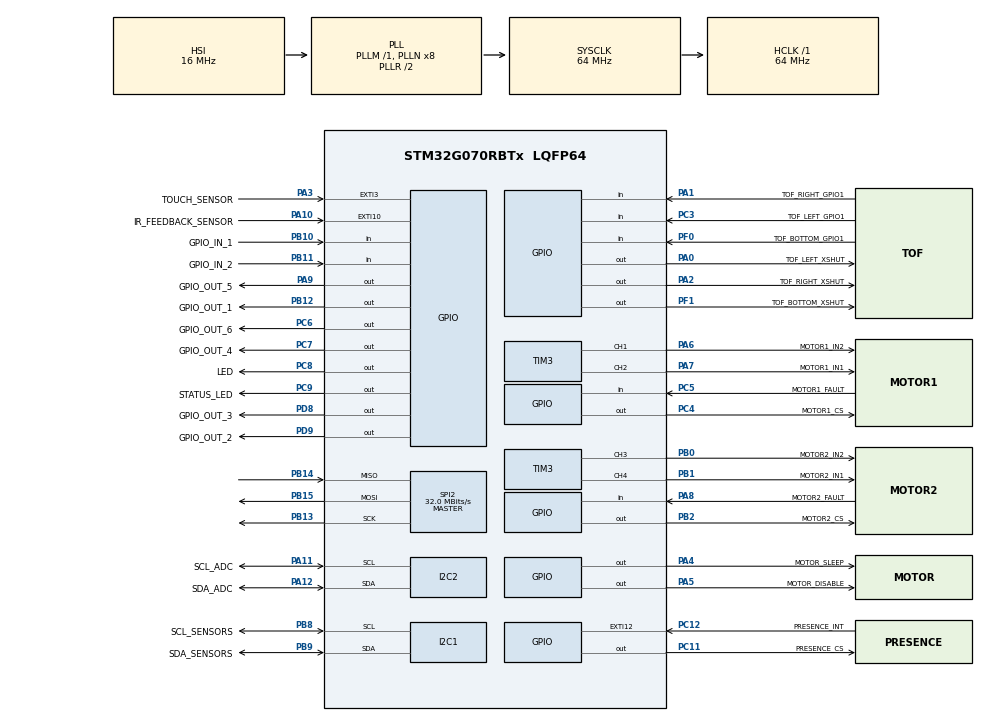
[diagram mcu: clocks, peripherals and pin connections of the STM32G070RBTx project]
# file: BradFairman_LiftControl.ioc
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I2C1.Timing=0x10707DBC
Mcu.Family=STM32G0
Mcu.Name=STM32G070RBTx
Mcu.Package=LQFP64
NVIC.EXTI2_3_IRQn=true\:0\:0\:false\:false\:true\:true\:true\:true
NVIC.EXTI4_15_IRQn=true\:0\:0\:false\:false\:true\:true\:true\:true
NVIC.TIM3_IRQn=true\:0\:0\:false\:false\:true\:true\:true\:true
PA0.GPIO_Label=TOF_LEFT_XSHUT
PA0.Signal=GPIO_Output
PA1.GPIO_Label=TOF_RIGHT_GPIO1
PA1.Signal=GPIO_Input
PA10.GPIO_Label=IR_FEEDBACK_SENSOR
PA10.GPIO_ModeDefaultEXTI=GPIO_MODE_IT_RISING_FALLING
PA10.Signal=GPXTI10
PA11\ [PA9].GPIO_Label=SCL_ADC
PA11\ [PA9].Mode=I2C
PA11\ [PA9].Signal=I2C2_SCL
PA12\ [PA10].GPIO_Label=SDA_ADC
PA12\ [PA10].Mode=I2C
PA12\ [PA10].Signal=I2C2_SDA
PA13.Mode=Serial_Wire
PA13.Signal=SYS_SWDIO
PA14-BOOT0.Mode=Serial_Wire
PA14-BOOT0.Signal=SYS_SWCLK
PA2.GPIO_Label=TOF_RIGHT_XSHUT
PA2.Signal=GPIO_Output
PA3.GPIO_Label=TOUCH_SENSOR
PA3.GPIO_ModeDefaultEXTI=GPIO_MODE_IT_RISING_FALLING
PA3.Signal=GPXTI3
PA4.GPIO_Label=MOTOR_SLEEP
PA4.Signal=GPIO_Output
PA5.GPIO_Label=MOTOR_DISABLE
PA5.Signal=GPIO_Output
PA6.GPIO_Label=MOTOR1_IN2
PA6.GPIO_PuPd=GPIO_PULLDOWN
PA6.GPIO_Speed=GPIO_SPEED_FREQ_HIGH
PA6.Signal=S_TIM3_CH1
PA7.GPIO_Label=MOTOR1_IN1
PA7.GPIO_PuPd=GPIO_PULLDOWN
PA7.GPIO_Speed=GPIO_SPEED_FREQ_HIGH
PA7.Signal=S_TIM3_CH2
PA8.GPIO_Label=MOTOR2_FAULT
PA8.Signal=GPIO_Input
PA9.GPIO_Label=GPIO_OUT_5
PA9.Signal=GPIO_Output
PB0.GPIO_Label=MOTOR2_IN2
PB0.GPIO_PuPd=GPIO_PULLDOWN
PB0.GPIO_Speed=GPIO_SPEED_FREQ_HIGH
PB0.Signal=S_TIM3_CH3
PB1.GPIO_Label=MOTOR2_IN1
PB1.GPIO_PuPd=GPIO_PULLDOWN
PB1.GPIO_Speed=GPIO_SPEED_FREQ_HIGH
PB1.Signal=S_TIM3_CH4
PB10.GPIO_Label=GPIO_IN_1
PB10.Signal=GPIO_Input
PB11.GPIO_Label=GPIO_IN_2
PB11.Signal=GPIO_Input
PB12.GPIO_Label=GPIO_OUT_1
PB12.Signal=GPIO_Output
PB13.Mode=Full_Duplex_Master
PB13.Signal=SPI2_SCK
PB14.Mode=Full_Duplex_Master
PB14.Signal=SPI2_MISO
PB15.Mode=Full_Duplex_Master
PB15.Signal=SPI2_MOSI
PB2.GPIO_Label=MOTOR2_CS
PB2.PinState=GPIO_PIN_SET
PB2.Signal=GPIO_Output
PB8.GPIO_Label=SCL_SENSORS
PB8.Mode=I2C
PB8.Signal=I2C1_SCL
PB9.GPIO_Label=SDA_SENSORS
PB9.Mode=I2C
PB9.Signal=I2C1_SDA
PC11.GPIO_Label=PRESENCE_CS
PC11.Signal=GPIO_Output
PC12.GPIO_Label=PRESENCE_INT
PC12.Signal=GPXTI12
PC3.GPIO_Label=TOF_LEFT_GPIO1
PC3.Signal=GPIO_Input
PC4.GPIO_Label=MOTOR1_CS
PC4.PinState=GPIO_PIN_SET
PC4.Signal=GPIO_Output
PC5.GPIO_Label=MOTOR1_FAULT
PC5.Signal=GPIO_Input
PC6.GPIO_Label=GPIO_OUT_6
PC6.Signal=GPIO_Output
PC7.GPIO_Label=GPIO_OUT_4
PC7.Signal=GPIO_Output
PC8.GPIO_Label=LED
PC8.Signal=GPIO_Output
PC9.GPIO_Label=STATUS_LED
PC9.Signal=GPIO_Output
PD8.GPIO_Label=GPIO_OUT_3
PD8.Signal=GPIO_Output
PD9.GPIO_Label=GPIO_OUT_2
PD9.Signal=GPIO_Output
PF0-OSC_IN\ (PF0).GPIO_Label=TOF_BOTTOM_GPIO1
PF0-OSC_IN\ (PF0).Signal=GPIO_Input
PF1-OSC_OUT\ (PF1).GPIO_Label=TOF_BOTTOM_XSHUT
PF1-OSC_OUT\ (PF1).Signal=GPIO_Output
ProjectManager.HeapSize=0x200
ProjectManager.StackSize=0x400
ProjectManager.TargetToolchain=STM32CubeIDE
RCC.ADCFreq_Value=64000000
RCC.AHBFreq_Value=64000000
RCC.CortexFreq_Value=64000000
RCC.EXTERNAL_CLOCK_VALUE=48000
RCC.HCLKFreq_Value=64000000
RCC.HSE_VALUE=8000000
RCC.HSI_VALUE=16000000
RCC.LSE_VALUE=32768
RCC.SYSCLKFreq_VALUE=64000000
RCC.SYSCLKSource=RCC_SYSCLKSOURCE_PLLCLK
RCC.VCOOutputFreq_Value=128000000
SH.S_TIM3_CH1.0=TIM3_CH1,PWM Generation1 CH1
SH.S_TIM3_CH2.0=TIM3_CH2,PWM Generation2 CH2
SH.S_TIM3_CH3.0=TIM3_CH3,PWM Generation3 CH3
SH.S_TIM3_CH4.0=TIM3_CH4,PWM Generation4 CH4
SPI2.CalculateBaudRate=32.0 MBits/s
SPI2.DataSize=SPI_DATASIZE_8BIT
SPI2.Direction=SPI_DIRECTION_2LINES
SPI2.Mode=SPI_MODE_MASTER
SPI2.VirtualType=VM_MASTER
TIM3.Channel-PWM\ Generation1\ CH1=TIM_CHANNEL_1
TIM3.Channel-PWM\ Generation2\ CH2=TIM_CHANNEL_2
TIM3.Channel-PWM\ Generation3\ CH3=TIM_CHANNEL_3
TIM3.Channel-PWM\ Generation4\ CH4=TIM_CHANNEL_4
VP_SYS_VS_DBSignals.Mode=DisableDeadBatterySignals
VP_TIM3_VS_ClockSourceINT.Mode=Internal
board=custom

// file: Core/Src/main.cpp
/* USER CODE BEGIN Header */
/**
  ******************************************************************************
  * @file           : main.c
  * @brief          : Main program body
  ******************************************************************************
  * @attention
  *
  * Copyright (c) 2024 STMicroelectronics.
  * All rights reserved.
  *
  * This software is licensed under terms that can be found in the LICENSE file
  * in the root directory of this software component.
  * If no LICENSE file comes with this software, it is provided AS-IS.
  *
  ******************************************************************************
  */
/* USER CODE END Header */
#include "main.h"

/* USER CODE BEGIN Includes */
#include <mainApp.hpp>
/* USER CODE END Includes */

I2C_HandleTypeDef hi2c1;
I2C_HandleTypeDef hi2c2;

SPI_HandleTypeDef hspi2;

TIM_HandleTypeDef htim3;

/* USER CODE BEGIN PV */
mainApp liftControl(&hspi2, &hi2c1, &hi2c2, &htim3);

/* USER CODE END PV */

void SystemClock_Config(void);
static void MX_GPIO_Init(void);
static void MX_I2C1_Init(void);
static void MX_I2C2_Init(void);
static void MX_SPI2_Init(void);
static void MX_TIM3_Init(void);
/* USER CODE BEGIN PFP */

//bool led_status = false;

/* USER CODE END PFP */

int main(void)
{

  /* MCU Configuration--------------------------------------------------------*/

  /* Reset of all peripherals, Initializes the Flash interface and the Systick. */
  HAL_Init();

  /* Configure the system clock */
  SystemClock_Config();

  /* Initialize all configured peripherals */
  MX_GPIO_Init();
  MX_I2C1_Init();
  MX_I2C2_Init();
  MX_SPI2_Init();
  MX_TIM3_Init();
  /* USER CODE BEGIN 2 */
  liftControl.initialize();

  liftControl.loop();

  /* USER CODE END 2 */

  /* Infinite loop */
  while (1)
  {

  }
}

void SystemClock_Config(void)
{
  RCC_OscInitTypeDef RCC_OscInitStruct = {0};
  RCC_ClkInitTypeDef RCC_ClkInitStruct = {0};

  /** Configure the main internal regulator output voltage
  */
  HAL_PWREx_ControlVoltageScaling(PWR_REGULATOR_VOLTAGE_SCALE1);

  /** Initializes the RCC Oscillators according to the specified parameters
  * in the RCC_OscInitTypeDef structure.
  */
  RCC_OscInitStruct.OscillatorType = RCC_OSCILLATORTYPE_HSI;
  RCC_OscInitStruct.HSIState = RCC_HSI_ON;
  RCC_OscInitStruct.HSIDiv = RCC_HSI_DIV1;
  RCC_OscInitStruct.HSICalibrationValue = RCC_HSICALIBRATION_DEFAULT;
  RCC_OscInitStruct.PLL.PLLState = RCC_PLL_ON;
  RCC_OscInitStruct.PLL.PLLSource = RCC_PLLSOURCE_HSI;
  RCC_OscInitStruct.PLL.PLLM = RCC_PLLM_DIV1;
  RCC_OscInitStruct.PLL.PLLN = 8;
  RCC_OscInitStruct.PLL.PLLP = RCC_PLLP_DIV2;
  RCC_OscInitStruct.PLL.PLLR = RCC_PLLR_DIV2;
  if (HAL_RCC_OscConfig(&RCC_OscInitStruct) != HAL_OK)
  {
    Error_Handler();
  }

  /** Initializes the CPU, AHB and APB buses clocks
  */
  RCC_ClkInitStruct.ClockType = RCC_CLOCKTYPE_HCLK|RCC_CLOCKTYPE_SYSCLK
                              |RCC_CLOCKTYPE_PCLK1;
  RCC_ClkInitStruct.SYSCLKSource = RCC_SYSCLKSOURCE_PLLCLK;
  RCC_ClkInitStruct.AHBCLKDivider = RCC_SYSCLK_DIV1;
  RCC_ClkInitStruct.APB1CLKDivider = RCC_HCLK_DIV1;

  if (HAL_RCC_ClockConfig(&RCC_ClkInitStruct, FLASH_LATENCY_2) != HAL_OK)
  {
    Error_Handler();
  }
}

static void MX_I2C1_Init(void)
{

  hi2c1.Instance = I2C1;
  hi2c1.Init.Timing = 0x10707DBC;
  hi2c1.Init.OwnAddress1 = 0;
  hi2c1.Init.AddressingMode = I2C_ADDRESSINGMODE_7BIT;
  hi2c1.Init.DualAddressMode = I2C_DUALADDRESS_DISABLE;
  hi2c1.Init.OwnAddress2 = 0;
  hi2c1.Init.OwnAddress2Masks = I2C_OA2_NOMASK;
  hi2c1.Init.GeneralCallMode = I2C_GENERALCALL_DISABLE;
  hi2c1.Init.NoStretchMode = I2C_NOSTRETCH_DISABLE;
  if (HAL_I2C_Init(&hi2c1) != HAL_OK)
  {
    Error_Handler();
  }

  /** Configure Analogue filter
  */
  if (HAL_I2CEx_ConfigAnalogFilter(&hi2c1, I2C_ANALOGFILTER_ENABLE) != HAL_OK)
  {
    Error_Handler();
  }

  /** Configure Digital filter
  */
  if (HAL_I2CEx_ConfigDigitalFilter(&hi2c1, 0) != HAL_OK)
  {
    Error_Handler();
  }

}

static void MX_I2C2_Init(void)
{

  hi2c2.Instance = I2C2;
  hi2c2.Init.Timing = 0x00303D5B;
  hi2c2.Init.OwnAddress1 = 0;
  hi2c2.Init.AddressingMode = I2C_ADDRESSINGMODE_7BIT;
  hi2c2.Init.DualAddressMode = I2C_DUALADDRESS_DISABLE;
  hi2c2.Init.OwnAddress2 = 0;
  hi2c2.Init.OwnAddress2Masks = I2C_OA2_NOMASK;
  hi2c2.Init.GeneralCallMode = I2C_GENERALCALL_DISABLE;
  hi2c2.Init.NoStretchMode = I2C_NOSTRETCH_DISABLE;
  if (HAL_I2C_Init(&hi2c2) != HAL_OK)
  {
    Error_Handler();
  }

  /** Configure Analogue filter
  */
  if (HAL_I2CEx_ConfigAnalogFilter(&hi2c2, I2C_ANALOGFILTER_ENABLE) != HAL_OK)
  {
    Error_Handler();
  }

  /** Configure Digital filter
  */
  if (HAL_I2CEx_ConfigDigitalFilter(&hi2c2, 0) != HAL_OK)
  {
    Error_Handler();
  }

}

static void MX_SPI2_Init(void)
{

  /* SPI2 parameter configuration*/
  hspi2.Instance = SPI2;
  hspi2.Init.Mode = SPI_MODE_MASTER;
  hspi2.Init.Direction = SPI_DIRECTION_2LINES;
  hspi2.Init.DataSize = SPI_DATASIZE_8BIT;
  hspi2.Init.CLKPolarity = SPI_POLARITY_LOW;
  hspi2.Init.CLKPhase = SPI_PHASE_1EDGE;
  hspi2.Init.NSS = SPI_NSS_SOFT;
  hspi2.Init.BaudRatePrescaler = SPI_BAUDRATEPRESCALER_2;
  hspi2.Init.FirstBit = SPI_FIRSTBIT_MSB;
  hspi2.Init.TIMode = SPI_TIMODE_DISABLE;
  hspi2.Init.CRCCalculation = SPI_CRCCALCULATION_DISABLE;
  hspi2.Init.CRCPolynomial = 7;
  hspi2.Init.CRCLength = SPI_CRC_LENGTH_DATASIZE;
  hspi2.Init.NSSPMode = SPI_NSS_PULSE_ENABLE;
  if (HAL_SPI_Init(&hspi2) != HAL_OK)
  {
    Error_Handler();
  }

}

static void MX_TIM3_Init(void)
{

  /* USER CODE BEGIN TIM3_Init 0 */
  uint32_t timer_clock = HAL_RCC_GetPCLK1Freq();
  uint32_t desired_pwm_freq = MOTOR_PWM_FREQ; // 10 kHz
//  uint32_t prescaler_val = timer_clock/1000000;
  uint32_t prescaler_val =(timer_clock / desired_pwm_freq) / 65535;
  uint32_t period_val = (timer_clock / desired_pwm_freq) - (1 + (prescaler_val*65535));  // 6400) - (3*65535)

  /* USER CODE END TIM3_Init 0 */

  TIM_ClockConfigTypeDef sClockSourceConfig = {0};
  TIM_MasterConfigTypeDef sMasterConfig = {0};
  TIM_OC_InitTypeDef sConfigOC = {0};

  htim3.Instance = TIM3;
  htim3.Init.Prescaler = prescaler_val;
  htim3.Init.CounterMode = TIM_COUNTERMODE_UP;
  htim3.Init.Period = period_val;
  htim3.Init.ClockDivision = TIM_CLOCKDIVISION_DIV1;
  htim3.Init.AutoReloadPreload = TIM_AUTORELOAD_PRELOAD_DISABLE;
  if (HAL_TIM_Base_Init(&htim3) != HAL_OK)
  {
    Error_Handler();
  }
  sClockSourceConfig.ClockSource = TIM_CLOCKSOURCE_INTERNAL;
  if (HAL_TIM_ConfigClockSource(&htim3, &sClockSourceConfig) != HAL_OK)
  {
    Error_Handler();
  }
  if (HAL_TIM_PWM_Init(&htim3) != HAL_OK)
  {
    Error_Handler();
  }
  sMasterConfig.MasterOutputTrigger = TIM_TRGO_RESET;
  sMasterConfig.MasterSlaveMode = TIM_MASTERSLAVEMODE_DISABLE;
  if (HAL_TIMEx_MasterConfigSynchronization(&htim3, &sMasterConfig) != HAL_OK)
  {
    Error_Handler();
  }
  sConfigOC.OCMode = TIM_OCMODE_PWM1;
  sConfigOC.Pulse = 0;
  sConfigOC.OCPolarity = TIM_OCPOLARITY_HIGH;
  sConfigOC.OCFastMode = TIM_OCFAST_DISABLE;
  if (HAL_TIM_PWM_ConfigChannel(&htim3, &sConfigOC, TIM_CHANNEL_1) != HAL_OK)
  {
    Error_Handler();
  }
  if (HAL_TIM_PWM_ConfigChannel(&htim3, &sConfigOC, TIM_CHANNEL_2) != HAL_OK)
  {
    Error_Handler();
  }
  if (HAL_TIM_PWM_ConfigChannel(&htim3, &sConfigOC, TIM_CHANNEL_3) != HAL_OK)
  {
    Error_Handler();
  }
  if (HAL_TIM_PWM_ConfigChannel(&htim3, &sConfigOC, TIM_CHANNEL_4) != HAL_OK)
  {
    Error_Handler();
  }
  HAL_TIM_MspPostInit(&htim3);

}

static void MX_GPIO_Init(void)
{
  GPIO_InitTypeDef GPIO_InitStruct = {0};

  /* GPIO Ports Clock Enable */
  __HAL_RCC_GPIOC_CLK_ENABLE();
  __HAL_RCC_GPIOF_CLK_ENABLE();
  __HAL_RCC_GPIOA_CLK_ENABLE();
  __HAL_RCC_GPIOB_CLK_ENABLE();
  __HAL_RCC_GPIOD_CLK_ENABLE();

  /*Configure GPIO pin Output Level */
  HAL_GPIO_WritePin(GPIOC, PRESENCE_CS_Pin|GPIO_OUT_6_Pin|GPIO_OUT_4_Pin|LED_Pin
                          |STATUS_LED_Pin, GPIO_PIN_RESET);

  /*Configure GPIO pin Output Level */
  HAL_GPIO_WritePin(TOF_BOTTOM_XSHUT_GPIO_Port, TOF_BOTTOM_XSHUT_Pin, GPIO_PIN_RESET);

  /*Configure GPIO pin Output Level */
  HAL_GPIO_WritePin(GPIOA, TOF_LEFT_XSHUT_Pin|TOF_RIGHT_XSHUT_Pin|MOTOR_SLEEP_Pin|MOTOR_DISABLE_Pin
                          |GPIO_OUT_5_Pin, GPIO_PIN_RESET);

  /*Configure GPIO pin Output Level */
  HAL_GPIO_WritePin(MOTOR1_CS_GPIO_Port, MOTOR1_CS_Pin, GPIO_PIN_SET);

  /*Configure GPIO pin Output Level */
  HAL_GPIO_WritePin(MOTOR2_CS_GPIO_Port, MOTOR2_CS_Pin, GPIO_PIN_SET);

  /*Configure GPIO pin Output Level */
  HAL_GPIO_WritePin(GPIO_OUT_1_GPIO_Port, GPIO_OUT_1_Pin, GPIO_PIN_RESET);

  /*Configure GPIO pin Output Level */
  HAL_GPIO_WritePin(GPIOD, GPIO_OUT_3_Pin|GPIO_OUT_2_Pin, GPIO_PIN_RESET);

  /*Configure GPIO pins : PRESENCE_CS_Pin MOTOR1_CS_Pin GPIO_OUT_6_Pin GPIO_OUT_4_Pin
                           LED_Pin STATUS_LED_Pin */
  GPIO_InitStruct.Pin = PRESENCE_CS_Pin|MOTOR1_CS_Pin|GPIO_OUT_6_Pin|GPIO_OUT_4_Pin
                          |LED_Pin|STATUS_LED_Pin;
  GPIO_InitStruct.Mode = GPIO_MODE_OUTPUT_PP;
  GPIO_InitStruct.Pull = GPIO_NOPULL;
  GPIO_InitStruct.Speed = GPIO_SPEED_FREQ_LOW;
  HAL_GPIO_Init(GPIOC, &GPIO_InitStruct);

  /*Configure GPIO pin : PRESENCE_INT_Pin */
  GPIO_InitStruct.Pin = PRESENCE_INT_Pin;
  GPIO_InitStruct.Mode = GPIO_MODE_IT_RISING;
  GPIO_InitStruct.Pull = GPIO_NOPULL;
  HAL_GPIO_Init(PRESENCE_INT_GPIO_Port, &GPIO_InitStruct);

  /*Configure GPIO pin : TOF_BOTTOM_GPIO1_Pin */
  GPIO_InitStruct.Pin = TOF_BOTTOM_GPIO1_Pin;
  GPIO_InitStruct.Mode = GPIO_MODE_INPUT;
  GPIO_InitStruct.Pull = GPIO_NOPULL;
  HAL_GPIO_Init(TOF_BOTTOM_GPIO1_GPIO_Port, &GPIO_InitStruct);

  /*Configure GPIO pin : TOF_BOTTOM_XSHUT_Pin */
  GPIO_InitStruct.Pin = TOF_BOTTOM_XSHUT_Pin;
  GPIO_InitStruct.Mode = GPIO_MODE_OUTPUT_PP;
  GPIO_InitStruct.Pull = GPIO_NOPULL;
  GPIO_InitStruct.Speed = GPIO_SPEED_FREQ_LOW;
  HAL_GPIO_Init(TOF_BOTTOM_XSHUT_GPIO_Port, &GPIO_InitStruct);

  /*Configure GPIO pins : TOF_LEFT_GPIO1_Pin MOTOR1_FAULT_Pin */
  GPIO_InitStruct.Pin = TOF_LEFT_GPIO1_Pin|MOTOR1_FAULT_Pin;
  GPIO_InitStruct.Mode = GPIO_MODE_INPUT;
  GPIO_InitStruct.Pull = GPIO_NOPULL;
  HAL_GPIO_Init(GPIOC, &GPIO_InitStruct);

  /*Configure GPIO pins : TOF_LEFT_XSHUT_Pin TOF_RIGHT_XSHUT_Pin MOTOR_SLEEP_Pin MOTOR_DISABLE_Pin
                           GPIO_OUT_5_Pin */
  GPIO_InitStruct.Pin = TOF_LEFT_XSHUT_Pin|TOF_RIGHT_XSHUT_Pin|MOTOR_SLEEP_Pin|MOTOR_DISABLE_Pin
                          |GPIO_OUT_5_Pin;
  GPIO_InitStruct.Mode = GPIO_MODE_OUTPUT_PP;
  GPIO_InitStruct.Pull = GPIO_NOPULL;
  GPIO_InitStruct.Speed = GPIO_SPEED_FREQ_LOW;
  HAL_GPIO_Init(GPIOA, &GPIO_InitStruct);

  /*Configure GPIO pins : TOF_RIGHT_GPIO1_Pin MOTOR2_FAULT_Pin */
  GPIO_InitStruct.Pin = TOF_RIGHT_GPIO1_Pin|MOTOR2_FAULT_Pin;
  GPIO_InitStruct.Mode = GPIO_MODE_INPUT;
  GPIO_InitStruct.Pull = GPIO_NOPULL;
  HAL_GPIO_Init(GPIOA, &GPIO_InitStruct);

  /*Configure GPIO pins : TOUCH_SENSOR_Pin IR_FEEDBACK_SENSOR_Pin */
  GPIO_InitStruct.Pin = TOUCH_SENSOR_Pin|IR_FEEDBACK_SENSOR_Pin;
  GPIO_InitStruct.Mode = GPIO_MODE_IT_RISING_FALLING;
  GPIO_InitStruct.Pull = GPIO_NOPULL;
  HAL_GPIO_Init(GPIOA, &GPIO_InitStruct);

  /*Configure GPIO pins : MOTOR2_CS_Pin GPIO_OUT_1_Pin */
  GPIO_InitStruct.Pin = MOTOR2_CS_Pin|GPIO_OUT_1_Pin;
  GPIO_InitStruct.Mode = GPIO_MODE_OUTPUT_PP;
  GPIO_InitStruct.Pull = GPIO_NOPULL;
  GPIO_InitStruct.Speed = GPIO_SPEED_FREQ_LOW;
  HAL_GPIO_Init(GPIOB, &GPIO_InitStruct);

  /*Configure GPIO pins : GPIO_IN_1_Pin GPIO_IN_2_Pin */
  GPIO_InitStruct.Pin = GPIO_IN_1_Pin|GPIO_IN_2_Pin;
  GPIO_InitStruct.Mode = GPIO_MODE_INPUT;
  GPIO_InitStruct.Pull = GPIO_NOPULL;
  HAL_GPIO_Init(GPIOB, &GPIO_InitStruct);

  /*Configure GPIO pins : GPIO_OUT_3_Pin GPIO_OUT_2_Pin */
  GPIO_InitStruct.Pin = GPIO_OUT_3_Pin|GPIO_OUT_2_Pin;
  GPIO_InitStruct.Mode = GPIO_MODE_OUTPUT_PP;
  GPIO_InitStruct.Pull = GPIO_NOPULL;
  GPIO_InitStruct.Speed = GPIO_SPEED_FREQ_LOW;
  HAL_GPIO_Init(GPIOD, &GPIO_InitStruct);

  /* EXTI interrupt init*/
  HAL_NVIC_SetPriority(EXTI2_3_IRQn, 0, 0);
  HAL_NVIC_EnableIRQ(EXTI2_3_IRQn);

  HAL_NVIC_SetPriority(EXTI4_15_IRQn, 0, 0);
  HAL_NVIC_EnableIRQ(EXTI4_15_IRQn);

}

void Error_Handler(void)
{
  __disable_irq();
  while (1)
  {
  }
}
